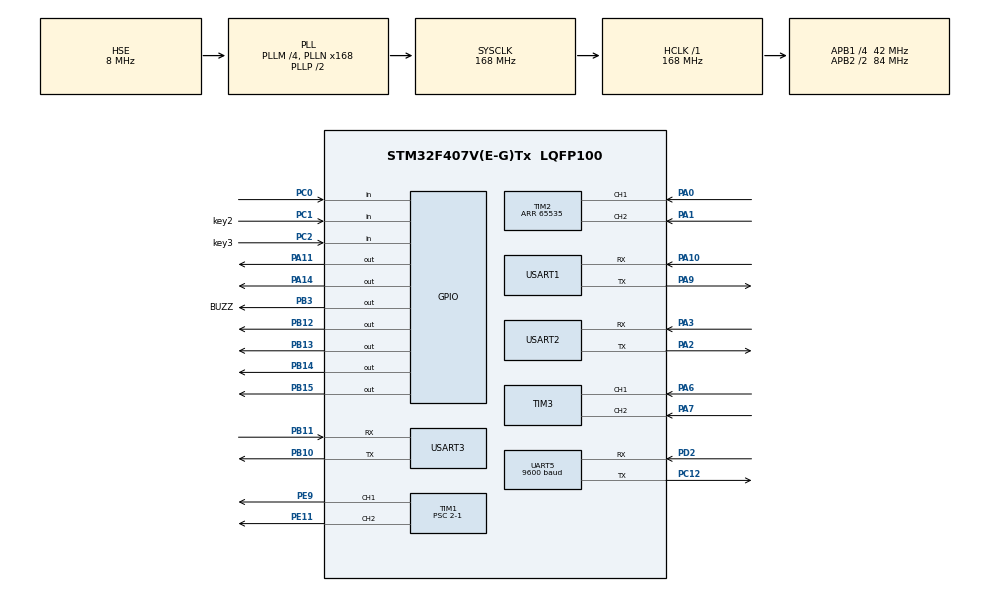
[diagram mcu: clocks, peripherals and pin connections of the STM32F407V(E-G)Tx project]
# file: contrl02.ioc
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Mcu.Family=STM32F4
Mcu.Name=STM32F407V(E-G)Tx
Mcu.Package=LQFP100
NVIC.PriorityGroup=NVIC_PRIORITYGROUP_4
NVIC.UART5_IRQn=true\:4\:0\:true\:false\:true\:true\:true
NVIC.USART1_IRQn=true\:5\:0\:true\:false\:true\:true\:true
NVIC.USART2_IRQn=true\:3\:0\:true\:false\:true\:true\:true
NVIC.USART3_IRQn=true\:2\:0\:true\:false\:true\:true\:true
PA0-WKUP.Signal=S_TIM2_CH1_ETR
PA1.Signal=S_TIM2_CH2
PA10.Mode=Asynchronous
PA10.Signal=USART1_RX
PA11.Signal=GPIO_Output
PA14.Signal=GPIO_Output
PA2.Mode=Asynchronous
PA2.Signal=USART2_TX
PA3.Mode=Asynchronous
PA3.Signal=USART2_RX
PA6.Signal=S_TIM3_CH1
PA7.Signal=S_TIM3_CH2
PA9.Mode=Asynchronous
PA9.Signal=USART1_TX
PB10.Mode=Asynchronous
PB10.Signal=USART3_TX
PB11.Mode=Asynchronous
PB11.Signal=USART3_RX
PB12.Signal=GPIO_Output
PB13.Signal=GPIO_Output
PB14.Signal=GPIO_Output
PB15.Signal=GPIO_Output
PB3.GPIO_Label=BUZZ
PB3.Signal=GPIO_Output
PC0.Signal=GPIO_Input
PC1.GPIO_Label=key2
PC1.GPIO_PuPd=GPIO_PULLUP
PC1.Signal=GPIO_Input
PC12.Mode=Asynchronous
PC12.Signal=UART5_TX
PC2.GPIO_Label=key3
PC2.GPIO_PuPd=GPIO_PULLUP
PC2.Signal=GPIO_Input
PD2.Mode=Asynchronous
PD2.Signal=UART5_RX
PE11.Signal=S_TIM1_CH2
PE9.Signal=S_TIM1_CH1
PH0-OSC_IN.Mode=HSE-External-Oscillator
PH0-OSC_IN.Signal=RCC_OSC_IN
PH1-OSC_OUT.Mode=HSE-External-Oscillator
PH1-OSC_OUT.Signal=RCC_OSC_OUT
ProjectManager.HeapSize=0x200
ProjectManager.StackSize=0x400
ProjectManager.TargetToolchain=MDK-ARM V5.27
RCC.48MHZClocksFreq_Value=84000000
RCC.AHBFreq_Value=168000000
RCC.APB1CLKDivider=RCC_HCLK_DIV4
RCC.APB1Freq_Value=42000000
RCC.APB1TimFreq_Value=84000000
RCC.APB2CLKDivider=RCC_HCLK_DIV2
RCC.APB2Freq_Value=84000000
RCC.APB2TimFreq_Value=168000000
RCC.CortexFreq_Value=168000000
RCC.HCLKFreq_Value=168000000
RCC.HSE_VALUE=8000000
RCC.HSI_VALUE=16000000
RCC.LSE_VALUE=32768
RCC.PLLM=4
RCC.PLLN=168
RCC.PLLSourceVirtual=RCC_PLLSOURCE_HSE
RCC.SYSCLKFreq_VALUE=168000000
RCC.SYSCLKSource=RCC_SYSCLKSOURCE_PLLCLK
RCC.VCOOutputFreq_Value=336000000
SH.S_TIM1_CH1.0=TIM1_CH1,PWM Generation1 CH1
SH.S_TIM1_CH2.0=TIM1_CH2,PWM Generation2 CH2
SH.S_TIM2_CH1_ETR.0=TIM2_CH1,Encoder_Interface
SH.S_TIM2_CH2.0=TIM2_CH2,Encoder_Interface
SH.S_TIM3_CH1.0=TIM3_CH1,Encoder_Interface
SH.S_TIM3_CH2.0=TIM3_CH2,Encoder_Interface
TIM1.Channel-PWM\ Generation1\ CH1=TIM_CHANNEL_1
TIM1.Channel-PWM\ Generation2\ CH2=TIM_CHANNEL_2
TIM1.Period=1000-1
TIM1.Prescaler=2-1
TIM2.EncoderMode=TIM_ENCODERMODE_TI12
TIM2.IC1Filter=15
TIM2.IC2Filter=15
TIM2.Period=65535
TIM3.EncoderMode=TIM_ENCODERMODE_TI12
TIM3.IC1Filter=15
TIM3.IC2Filter=15
UART5.BaudRate=9600
UART5.VirtualMode=Asynchronous
USART1.VirtualMode=VM_ASYNC
USART2.VirtualMode=VM_ASYNC
USART3.VirtualMode=VM_ASYNC
VP_TIM1_VS_ClockSourceINT.Mode=Internal
board=custom

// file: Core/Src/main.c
/* USER CODE BEGIN Header */
/**
  ******************************************************************************
  * @file           : main.c
  * @brief          : Main program body
  ******************************************************************************
  * @attention
  *
  * <h2><center>&copy; Copyright (c) 2021 STMicroelectronics.
  * All rights reserved.</center></h2>
  *
  * This software component is licensed by ST under BSD 3-Clause license,
  * the "License"; You may not use this file except in compliance with the
  * License. You may obtain a copy of the License at:
  *                        opensource.org/licenses/BSD-3-Clause
  *
  ******************************************************************************
  */
/* USER CODE END Header */
#include "main.h"
#include "tim.h"
#include "usart.h"
#include "gpio.h"

/* USER CODE BEGIN Includes */
#include "chasis.h"
#include "stdio.h"
/* USER CODE END Includes */

void SystemClock_Config(void);

int main(void)
{

  /* MCU Configuration--------------------------------------------------------*/

  /* Reset of all peripherals, Initializes the Flash interface and the Systick. */
  HAL_Init();

  /* Configure the system clock */
  SystemClock_Config();

  /* Initialize all configured peripherals */

  MX_GPIO_Init();
  MX_USART1_UART_Init();
  MX_USART3_UART_Init();
  MX_TIM1_Init();
  MX_USART2_UART_Init();
  MX_UART5_Init();
  MX_TIM2_Init();
  MX_TIM3_Init();
  /* USER CODE BEGIN 2 */
  Main_Setup();
  /* USER CODE END 2 */

  /* Infinite loop */
  while (1)
  {

    /* USER CODE BEGIN 3 */
		 Main_Loop();
  }
  /* USER CODE END 3 */
}

void SystemClock_Config(void)
{
  RCC_OscInitTypeDef RCC_OscInitStruct = {0};
  RCC_ClkInitTypeDef RCC_ClkInitStruct = {0};

  /** Configure the main internal regulator output voltage
  */
  __HAL_RCC_PWR_CLK_ENABLE();
  __HAL_PWR_VOLTAGESCALING_CONFIG(PWR_REGULATOR_VOLTAGE_SCALE1);
  /** Initializes the RCC Oscillators according to the specified parameters
  * in the RCC_OscInitTypeDef structure.
  */
  RCC_OscInitStruct.OscillatorType = RCC_OSCILLATORTYPE_HSE;
  RCC_OscInitStruct.HSEState = RCC_HSE_ON;
  RCC_OscInitStruct.PLL.PLLState = RCC_PLL_ON;
  RCC_OscInitStruct.PLL.PLLSource = RCC_PLLSOURCE_HSE;
  RCC_OscInitStruct.PLL.PLLM = 4;
  RCC_OscInitStruct.PLL.PLLN = 168;
  RCC_OscInitStruct.PLL.PLLP = RCC_PLLP_DIV2;
  RCC_OscInitStruct.PLL.PLLQ = 4;
  if (HAL_RCC_OscConfig(&RCC_OscInitStruct) != HAL_OK)
  {
    Error_Handler();
  }
  /** Initializes the CPU, AHB and APB buses clocks
  */
  RCC_ClkInitStruct.ClockType = RCC_CLOCKTYPE_HCLK|RCC_CLOCKTYPE_SYSCLK
                              |RCC_CLOCKTYPE_PCLK1|RCC_CLOCKTYPE_PCLK2;
  RCC_ClkInitStruct.SYSCLKSource = RCC_SYSCLKSOURCE_PLLCLK;
  RCC_ClkInitStruct.AHBCLKDivider = RCC_SYSCLK_DIV1;
  RCC_ClkInitStruct.APB1CLKDivider = RCC_HCLK_DIV4;
  RCC_ClkInitStruct.APB2CLKDivider = RCC_HCLK_DIV2;

  if (HAL_RCC_ClockConfig(&RCC_ClkInitStruct, FLASH_LATENCY_5) != HAL_OK)
  {
    Error_Handler();
  }
}

/* USER CODE BEGIN 4 */
int fputc(int ch, FILE *f)
{
 uint8_t temp[1] = {ch};
 HAL_UART_Transmit(&huart1, temp, 1, 2);
 return ch;
}

/* USER CODE END 4 */

void Error_Handler(void)
{
  __disable_irq();
  while (1)
  {
  }
}

/************************ (C) COPYRIGHT STMicroelectronics *****END OF FILE****/
